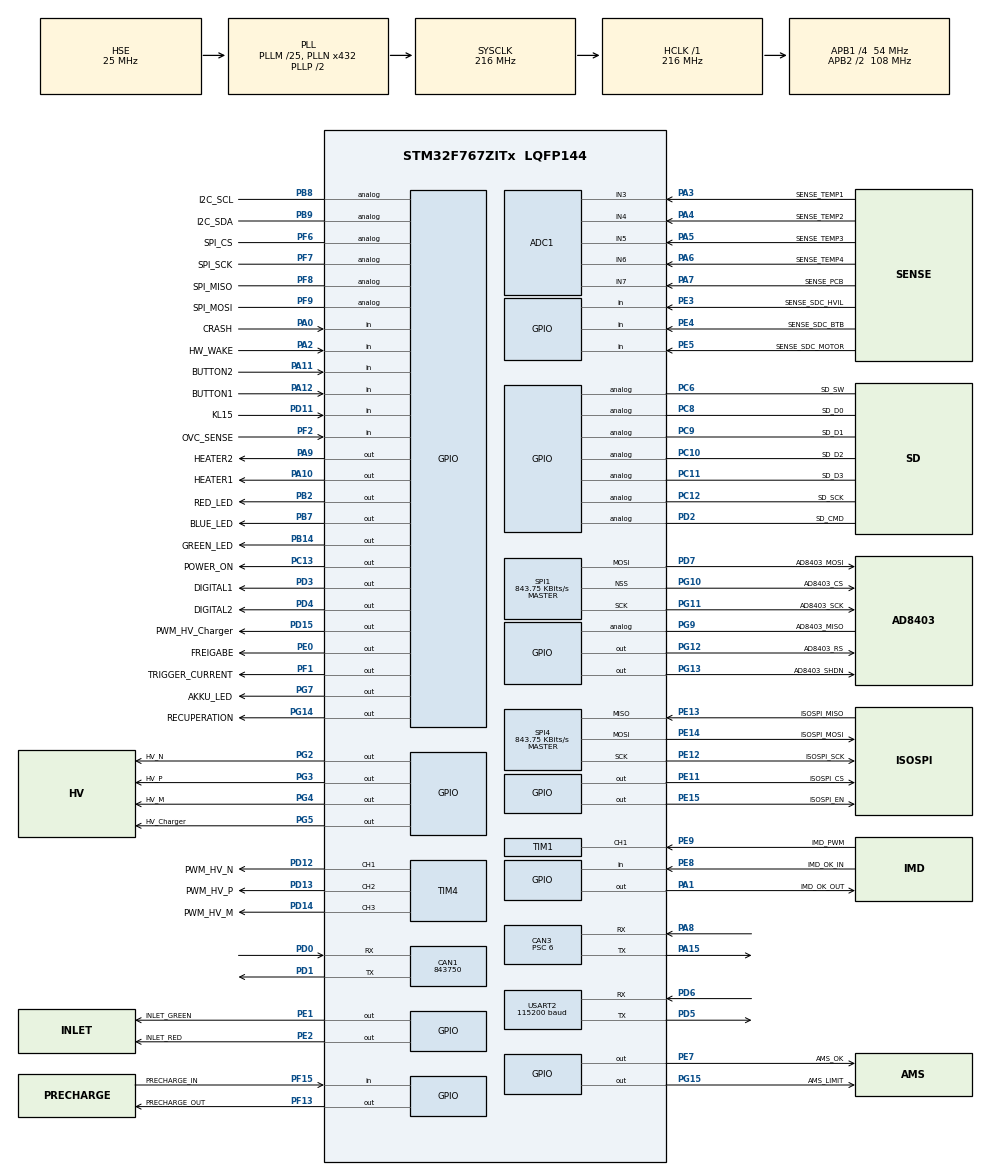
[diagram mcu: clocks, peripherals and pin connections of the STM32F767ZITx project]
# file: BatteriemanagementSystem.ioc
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ADC1.Channel-0\#ChannelRegularConversion=ADC_CHANNEL_TEMPSENSOR
ADC1.NbrOfConversion=1
ADC1.NbrOfConversionFlag=1
ADC1.Rank-0\#ChannelRegularConversion=1
ADC1.SamplingTime-0\#ChannelRegularConversion=ADC_SAMPLETIME_15CYCLES
ADC1.ScanConvMode=ADC_SCAN_DISABLE
ADC1.master=1
CAN1.BS1=CAN_BS1_2TQ
CAN1.BS2=CAN_BS2_1TQ
CAN1.CalculateBaudRate=843750
CAN1.CalculateTimeBit=1185
CAN1.CalculateTimeQuantum=296.2962962962963
CAN3.BS1=CAN_BS1_15TQ
CAN3.BS2=CAN_BS2_2TQ
CAN3.CalculateBaudRate=500000
CAN3.CalculateTimeBit=2000
CAN3.CalculateTimeQuantum=111.11111111111111
CAN3.Prescaler=6
Mcu.Family=STM32F7
Mcu.Name=STM32F767ZITx
Mcu.Package=LQFP144
NVIC.CAN3_RX0_IRQn=true\:0\:0\:false\:false\:false\:true\:true\:true
NVIC.CAN3_TX_IRQn=true\:0\:0\:false\:false\:false\:true\:true\:true
NVIC.PriorityGroup=NVIC_PRIORITYGROUP_4
NVIC.TIM1_CC_IRQn=true\:0\:0\:false\:false\:true\:true\:true\:true
PA0/WKUP.GPIO_Label=CRASH
PA0/WKUP.Signal=GPIO_Input
PA1.GPIO_Label=IMD_OK_OUT
PA1.Signal=GPIO_Output
PA10.GPIO_Label=HEATER1
PA10.Signal=GPIO_Output
PA11.GPIO_Label=BUTTON2
PA11.Signal=GPIO_Input
PA12.GPIO_Label=BUTTON1
PA12.Signal=GPIO_Input
PA13.GPIO_Label=TMS
PA13.Mode=Trace_Asynchronous_SW
PA13.Signal=SYS_JTMS-SWDIO
PA14.GPIO_Label=TCK
PA14.Mode=Trace_Asynchronous_SW
PA14.Signal=SYS_JTCK-SWCLK
PA15.Mode=CAN_Activate
PA15.Signal=CAN3_TX
PA2.GPIO_Label=HW_WAKE
PA2.Signal=GPIO_Input
PA3.GPIO_Label=SENSE_TEMP1
PA3.Signal=SharedAnalog_PA3
PA4.GPIO_Label=SENSE_TEMP2
PA4.Signal=SharedAnalog_PA4
PA5.GPIO_Label=SENSE_TEMP3
PA5.Signal=SharedAnalog_PA5
PA6.GPIO_Label=SENSE_TEMP4
PA6.Signal=SharedAnalog_PA6
PA7.GPIO_Label=SENSE_PCB
PA7.Signal=SharedAnalog_PA7
PA8.Mode=CAN_Activate
PA8.Signal=CAN3_RX
PA9.GPIO_Label=HEATER2
PA9.Signal=GPIO_Output
PB14.GPIO_Label=GREEN_LED
PB14.Signal=GPIO_Output
PB2.GPIO_Label=RED_LED
PB2.GPIO_Speed=GPIO_SPEED_FREQ_LOW
PB2.Signal=GPIO_Output
PB3.GPIO_Label=SWO
PB3.Mode=Trace_Asynchronous_SW
PB3.Signal=SYS_JTDO-SWO
PB7.GPIO_FM7=__NULL
PB7.GPIO_Label=BLUE_LED
PB7.Signal=GPIO_Output
PB8.GPIO_Label=I2C_SCL
PB8.Signal=GPIO_Analog
PB9.GPIO_Label=I2C_SDA
PB9.Signal=GPIO_Analog
PC10.GPIO_Label=SD_D2
PC10.Signal=GPIO_Analog
PC11.GPIO_Label=SD_D3
PC11.Signal=GPIO_Analog
PC12.GPIO_Label=SD_SCK
PC12.Signal=GPIO_Analog
PC13.GPIO_Label=POWER_ON
PC13.Signal=GPIO_Output
PC14/OSC32_IN.Mode=LSE-External-Oscillator
PC14/OSC32_IN.Signal=RCC_OSC32_IN
PC15/OSC32_OUT.Mode=LSE-External-Oscillator
PC15/OSC32_OUT.Signal=RCC_OSC32_OUT
PC6.GPIO_Label=SD_SW
PC6.Signal=GPIO_Analog
PC8.GPIO_Label=SD_D0
PC8.Signal=GPIO_Analog
PC9.GPIO_Label=SD_D1
PC9.Signal=GPIO_Analog
PD0.Mode=CAN_Activate
PD0.Signal=CAN1_RX
PD1.Mode=CAN_Activate
PD1.Signal=CAN1_TX
PD11.GPIO_Label=KL15
PD11.Signal=GPIO_Input
PD12.GPIO_Label=PWM_HV_N
PD12.Signal=S_TIM4_CH1
PD13.GPIO_Label=PWM_HV_P
PD13.Signal=S_TIM4_CH2
PD14.GPIO_Label=PWM_HV_M
PD14.Signal=S_TIM4_CH3
PD15.GPIO_Label=PWM_HV_Charger
PD15.Signal=GPIO_Output
PD2.GPIO_Label=SD_CMD
PD2.Signal=GPIO_Analog
PD3.GPIO_Label=DIGITAL1
PD3.Signal=GPIO_Output
PD4.GPIO_Label=DIGITAL2
PD4.Signal=GPIO_Output
PD5.Mode=Asynchronous
PD5.Signal=USART2_TX
PD6.Mode=Asynchronous
PD6.Signal=USART2_RX
PD7.GPIO_Label=AD8403_MOSI
PD7.Mode=TX_Only_Simplex_Unidirect_Master
PD7.Signal=SPI1_MOSI
PE0.GPIO_Label=FREIGABE
PE0.Signal=GPIO_Output
PE1.GPIO_Label=INLET_GREEN
PE1.Signal=GPIO_Output
PE11.GPIO_Label=ISOSPI_CS
PE11.PinState=GPIO_PIN_SET
PE11.Signal=GPIO_Output
PE12.GPIO_Label=ISOSPI_SCK
PE12.Mode=Full_Duplex_Master
PE12.Signal=SPI4_SCK
PE13.GPIO_Label=ISOSPI_MISO
PE13.Mode=Full_Duplex_Master
PE13.Signal=SPI4_MISO
PE14.GPIO_Label=ISOSPI_MOSI
PE14.Mode=Full_Duplex_Master
PE14.Signal=SPI4_MOSI
PE15.GPIO_Label=ISOSPI_EN
PE15.Signal=GPIO_Output
PE2.GPIO_Label=INLET_RED
PE2.Signal=GPIO_Output
PE3.GPIO_Label=SENSE_SDC_HVIL
PE3.Signal=GPIO_Input
PE4.GPIO_Label=SENSE_SDC_BTB
PE4.Signal=GPIO_Input
PE5.GPIO_Label=SENSE_SDC_MOTOR
PE5.Signal=GPIO_Input
PE7.GPIO_Label=AMS_OK
PE7.Signal=GPIO_Output
PE8.GPIO_Label=IMD_OK_IN
PE8.Signal=GPIO_Input
PE9.GPIO_Label=IMD_PWM
PE9.Signal=S_TIM1_CH1
PF1.GPIO_Label=TRIGGER_CURRENT
PF1.Signal=GPIO_Output
PF13.GPIO_Label=PRECHARGE_OUT
PF13.Signal=GPIO_Output
PF15.GPIO_Label=PRECHARGE_IN
PF15.Signal=GPIO_Input
PF2.GPIO_Label=OVC_SENSE
PF2.Signal=GPIO_Input
PF6.GPIO_Label=SPI_CS
PF6.Signal=GPIO_Analog
PF7.GPIO_Label=SPI_SCK
PF7.Signal=GPIO_Analog
PF8.GPIO_Label=SPI_MISO
PF8.Signal=GPIO_Analog
PF9.GPIO_Label=SPI_MOSI
PF9.Signal=GPIO_Analog
PG10.GPIO_Label=AD8403_CS
PG10.Mode=NSS_Signal_Hard_Output
PG10.Signal=SPI1_NSS
PG11.GPIO_Label=AD8403_SCK
PG11.Mode=TX_Only_Simplex_Unidirect_Master
PG11.Signal=SPI1_SCK
PG12.GPIO_Label=AD8403_RS
PG12.Signal=GPIO_Output
PG13.GPIO_Label=AD8403_SHDN
PG13.Signal=GPIO_Output
PG14.GPIO_Label=RECUPERATION
PG14.Signal=GPIO_Output
PG15.GPIO_Label=AMS_LIMIT
PG15.Signal=GPIO_Output
PG2.GPIO_Label=HV_N
PG2.Signal=GPIO_Output
PG3.GPIO_Label=HV_P
PG3.Signal=GPIO_Output
PG4.GPIO_Label=HV_M
PG4.Signal=GPIO_Output
PG5.GPIO_Label=HV_Charger
PG5.Signal=GPIO_Output
PG7.GPIO_Label=AKKU_LED
PG7.Signal=GPIO_Output
PG9.GPIO_Label=AD8403_MISO
PG9.Signal=GPIO_Analog
PH0/OSC_IN.GPIO_Label=RCC_OSC_IN
PH0/OSC_IN.Mode=HSE-External-Oscillator
PH0/OSC_IN.Signal=RCC_OSC_IN
PH1/OSC_OUT.GPIO_Label=RCC_OSC_OUT
PH1/OSC_OUT.Mode=HSE-External-Oscillator
PH1/OSC_OUT.Signal=RCC_OSC_OUT
ProjectManager.HeapSize=0x200
ProjectManager.StackSize=0x400
ProjectManager.TargetToolchain=STM32CubeIDE
RCC.48MHZClocksFreq_Value=24000000
RCC.AHBFreq_Value=216000000
RCC.APB1CLKDivider=RCC_HCLK_DIV4
RCC.APB1Freq_Value=54000000
RCC.APB1TimFreq_Value=108000000
RCC.APB2CLKDivider=RCC_HCLK_DIV2
RCC.APB2Freq_Value=108000000
RCC.APB2TimFreq_Value=216000000
RCC.CortexFreq_Value=216000000
RCC.HCLKFreq_Value=216000000
RCC.HSE_VALUE=25000000
RCC.HSI_VALUE=16000000
RCC.PLL48CLockSelection=RCC_CLK48SOURCE_PLLSAIP
RCC.PLLM=25
RCC.PLLMUL=RCC_PLL_MUL9
RCC.PLLN=432
RCC.PLLQ=8
RCC.PLLSAIP=RCC_PLLSAIP_DIV8
RCC.PLLSourceVirtual=RCC_PLLSOURCE_HSE
RCC.PRESCALERUSB=RCC_USBCLKSOURCE_PLL_DIV1_5
RCC.RCC_MCO2Source=RCC_MCO2SOURCE_HSE
RCC.RTCClockSelection=RCC_RTCCLKSOURCE_LSE
RCC.SYSCLKFreq_VALUE=216000000
RCC.SYSCLKSource=RCC_SYSCLKSOURCE_PLLCLK
RCC.SYSCLKSourceVirtual=RCC_SYSCLKSOURCE_PLLCLK
RCC.USBFreq_Value=24000000
RCC.VCOOutputFreq_Value=432000000
SH.S_TIM1_CH1.0=TIM1_CH1,PWM_Input_1
SH.S_TIM4_CH1.0=TIM4_CH1,PWM Generation1 CH1
SH.S_TIM4_CH2.0=TIM4_CH2,PWM Generation2 CH2
SH.S_TIM4_CH3.0=TIM4_CH3,PWM Generation3 CH3
SH.SharedAnalog_PA3.0=GPIO_Analog
SH.SharedAnalog_PA3.1=ADC1_IN3,IN3
SH.SharedAnalog_PA4.0=GPIO_Analog
SH.SharedAnalog_PA4.1=ADC1_IN4,IN4
SH.SharedAnalog_PA5.0=GPIO_Analog
SH.SharedAnalog_PA5.1=ADC1_IN5,IN5
SH.SharedAnalog_PA6.0=GPIO_Analog
SH.SharedAnalog_PA6.1=ADC1_IN6,IN6
SH.SharedAnalog_PA7.0=GPIO_Analog
SH.SharedAnalog_PA7.1=ADC1_IN7,IN7
SPI1.BaudRatePrescaler=SPI_BAUDRATEPRESCALER_128
SPI1.CalculateBaudRate=843.75 KBits/s
SPI1.DataSize=SPI_DATASIZE_8BIT
SPI1.Direction=SPI_DIRECTION_2LINES
SPI1.Mode=SPI_MODE_MASTER
SPI1.NSSPMode=SPI_NSS_PULSE_ENABLE
SPI1.VirtualNSS=VM_NSSHARD
SPI1.VirtualType=VM_MASTER
SPI4.BaudRatePrescaler=SPI_BAUDRATEPRESCALER_128
SPI4.CLKPhase=SPI_PHASE_2EDGE
SPI4.CLKPolarity=SPI_POLARITY_HIGH
SPI4.CRCCalculation=SPI_CRCCALCULATION_DISABLE
SPI4.CalculateBaudRate=843.75 KBits/s
SPI4.DataSize=SPI_DATASIZE_8BIT
SPI4.Direction=SPI_DIRECTION_2LINES
SPI4.FirstBit=SPI_FIRSTBIT_MSB
SPI4.Mode=SPI_MODE_MASTER
SPI4.VirtualType=VM_MASTER
TIM1.AutoReloadPreload=TIM_AUTORELOAD_PRELOAD_DISABLE
TIM1.ClockDivision=TIM_CLOCKDIVISION_DIV1
TIM1.ICPolarity_1=TIM_INPUTCHANNELPOLARITY_RISING
TIM1.Period=65535
TIM1.Prescaler=675 - 1
TIM4.Channel-PWM\ Generation1\ CH1=TIM_CHANNEL_1
TIM4.Channel-PWM\ Generation2\ CH2=TIM_CHANNEL_2
TIM4.Channel-PWM\ Generation3\ CH3=TIM_CHANNEL_3
USART2.BaudRate=115200
USART2.VirtualMode-Asynchronous=VM_ASYNC
VP_ADC1_TempSens_Input.Mode=IN-TempSens
VP_TIM1_VS_ClockSourceINT.Mode=Internal
board=NUCLEO-F767ZI

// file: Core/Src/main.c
/* USER CODE BEGIN Header */
/**
  ******************************************************************************
  * @file           : main.c
  * @brief          : Main program body
  ******************************************************************************
  * @attention
  *
  * <h2><center>&copy; Copyright (c) 2020 STMicroelectronics.
  * All rights reserved.</center></h2>
  *
  * This software component is licensed by ST under BSD 3-Clause license,
  * the "License"; You may not use this file except in compliance with the
  * License. You may obtain a copy of the License at:
  *                        opensource.org/licenses/BSD-3-Clause
  *
  ******************************************************************************
  */
/* USER CODE END Header */
#include "main.h"
#include "adc.h"
#include "can.h"
#include "spi.h"
#include "tim.h"
#include "usart.h"
#include "gpio.h"

/* USER CODE BEGIN Includes */
#include "BatteriemanagementSystem.h"
#include <math.h>
/* USER CODE END Includes */

/* USER CODE BEGIN PTD */
// TODO:
// FIXME:
// xxx: Schlechte Performance
/* USER CODE END PTD */

/* USER CODE BEGIN PV */
// ADC Array
static uint16_t ADC_VAL[8] = {0};

// Fehler Speicher CAN-Bus
uint8_t can_online = 0;

// IMD Variablen fuer Timer
static volatile uint16_t rising = 0, falling = 0;
static volatile uint8_t pwm_change = 0;
/* USER CODE END PV */

void SystemClock_Config(void);
/* USER CODE BEGIN PFP */
void checkSDC (void);
void sortCAN (void);

/* USER CODE END PFP */

int main(void)
{

  /* USER CODE BEGIN 1 */
	// BMS Statemaschine Zeitvariablen
	uint32_t timeStandby = 0, timeErrorLED = 0;
	uint32_t timeZyklus = 0, lasttimeZyklus = 0;

	// BMS Abfrage Zeitvariablen
	uint32_t timeBMSWork = 0;

	// BMS CAN-Bus Zeitvariable
	uint32_t timeBAMO = 0, timeMOTOR = 0, timeStromHV = 0;

	// Zeitvariable Precharge
	uint32_t timePrecharge = 0;

	// CAN-Bus Receive Message
	CAN_message_t RxMessage;

	// Anforderung Motorsteuergeraet Drive-Modus aktivieren
	bool ActivDrive = false;
	Statemaschine mStrg = {{Start, true, false, false, false}};

#if STROM_HV_AVAILABLE == 1
	// Stromsensor Nachrichten definieren
	stromsensor_ivtmod current, voltage1;									//voltage2, voltage3;
#endif

	// IMD Variablen fuer Berechnung
	uint32_t timer1Periode = 0, timeIMD = 0;

	// Testvariablen
	uint32_t zweisekunden = 0;

#ifdef DEBUG_DWT
	// Variablen fuer Data Watchpoint Trigger
	uint32_t DWT_count = 0, DWT_count1 = 0, DWT_count2 = 0, test = 0;
#endif
  /* USER CODE END 1 */

  /* MCU Configuration--------------------------------------------------------*/

  /* Reset of all peripherals, Initializes the Flash interface and the Systick. */
  HAL_Init();

  /* Configure the system clock */
  SystemClock_Config();

  /* USER CODE BEGIN SysInit */
	MX_USART2_UART_Init();

	// Uart initialisieren
	initBasicUart(&huart2);

#ifdef DEBUG
	app_info();
	HAL_Delay(3000);
#endif

#if MOTOR_AVAILABLE != 1
	#if TISCHAUFBAU == 1
		sdc_in.Anlassen = true;
	#endif
#endif

	uartTransmit("Start\n", 6);
  /* USER CODE END SysInit */

  /* Initialize all configured peripherals */
  MX_GPIO_Init();
  MX_CAN1_Init();
  MX_SPI4_Init();
  MX_USART2_UART_Init();
  MX_ADC1_Init();
  MX_TIM1_Init();
  MX_TIM4_Init();
  MX_SPI1_Init();
  MX_CAN3_Init();
  /* USER CODE BEGIN 2 */

	// Timer 1 fuer IMD PWM-Eingang aktivieren
	if (HAL_TIM_Base_Init(&htim1) != HAL_OK);
	if (HAL_TIM_IC_Start_IT(&htim1, TIM_CHANNEL_1) != HAL_OK);
	if (HAL_TIM_IC_Start_IT(&htim1, TIM_CHANNEL_2) != HAL_OK);
	timer1Periode = (HAL_RCC_GetPCLK2Freq() / (htim1.Init.Prescaler / 2));

	// Uart initialisieren
	initBasicUart(&huart2);

	// CAN-Bus initalisieren
	CANinit(RX_SIZE_16, TX_SIZE_16);
	CAN_config();

	// System Selbsterhaltung einschalten
	system_out.PowerOn = true;

	// BMS initialisieren
	if (bms_init() != false)
	{
		uartTransmit("BMS gestartet\n", 14);
		system_out.AmsOK = true;
		system_out.AmsLimit = true;
	}
	else
	{
		uartTransmit("BMS konnte nicht gestartet werden\n", 34);
		system_out.AmsOK = false;
		system_out.AmsLimit = false;
//		setStatus(StateError);
	}

	// IMD Fehler zuruecksetzen bei Systemstart
	system_out.ImdOK = true;

	// CAN-Nachrichten loeschen
	clearCAN();

#ifdef DEBUG
	#define MAINWHILE							"\nStarte While Schleife\n"
	uartTransmit(MAINWHILE, sizeof(MAINWHILE));
#endif

	timeZyklus = millis();

	// Nach erfolgreicher Initialisiserung aller Konfigurationen
	setState(Ready);

	ltc6811_validate_balance();
  /* USER CODE END 2 */

  /* Infinite loop */
  /* USER CODE BEGIN WHILE */
	while (1)
	{
#ifdef DEBUG_ZYKLUS
		uartTransmit("Zykluszeit:\t\t", 13);
		uartTransmitNumber(millis() - timeZyklus, 10);
		uartTransmit("\n", 1);
#endif

		lasttimeZyklus = timeZyklus;
		timeZyklus = millis();
    /* USER CODE END WHILE */

    /* USER CODE BEGIN 3 */
		// Alle Eingaenge einlesen
		readall_inputs();

		// Alle ADC einlesen
		ADC_VAL[0] = ADC_STMTemperatur();
		ADC_VAL[1] = ADC_PCBTemperatur();
		ADC_VAL[2] = ADC_KL15();
		ADC_VAL[3] = ADC_KL30_Relais();
		ADC_VAL[4] = ADC_Temp1();
		ADC_VAL[5] = ADC_Temp2();
		ADC_VAL[6] = ADC_Temp3();
		ADC_VAL[7] = ADC_Temp4();

		// Sortiere CAN-Daten auf CAN-Buffer
		sortCAN();

		// Lese IMD Status ein
		// Wenn sich der Pegel am IMD_PWM aendert
		if (pwm_change == 1)
		{
			// IMD Werte berechnen
			if (rising != 0 && falling != 0)
			{
				// Berechne DutyCycle und Frequenzy von IMD_PWM
				uint16_t imd_diff = getDifference(rising, falling);
				imd.DutyCycle = 100 - round((float)(imd_diff * 100) / (float)rising);
				imd.Frequency = timer1Periode / rising;
			}

			// Alle 5s den IMD-Status auslesen
			if (millis() > (timeIMD + 5000))
			{
				imd_status();
				timeIMD = millis();
			}

			pwm_change = 0;
		}

		// Lese CAN-Nachrichten ein
		if (CAN_available() >= 1)
		{
			CANread(&RxMessage);

			switch (RxMessage.id)
			{
#if BAMOCAR_AVAILABLE == 1
				// Bamocar ID
				case BAMOCAR_CAN_RX:
				{
					can_online |= (1 << 0);
					timeBAMO = millis();

					setStatus(StateNormal);

					break;
				}
#endif

#if MOTOR_AVAILABLE == 1
				// Motorsteuergeraet Status ID
				case MOTOR_CAN_STATUS:
				{
					can_online |= (1 << 1);
					timeMOTOR = millis();

					setStatus(StateNormal);

					mStrg.Status = RxMessage.buf[0];

					break;
				}

				// Motorsteuergeraet Digital Input ID
				case MOTOR_CAN_DIGITAL_IN:
				{
					// TODO: Zuordnung Signal Bit
					// Abfrage Anlasser, Default 1, Geschaltet 0
					if (~RxMessage.buf[2] & (1 << 7))
					{
						// Anlasser Pin von Motorsteuergeraet abspeichern
						sdc_in.Anlassen = true;
					}

					// Abrage ASR1
					if ((RxMessage.buf[5] & (1 << 0)) && ((mStrg.State & ReadyToDrive) | (mStrg.State & Drive)))
					{
						// DriveMode aktivieren
						ActivDrive = true;
					}

					break;
				}
#endif

#if STROM_HV_AVAILABLE == 1
				// Stromwert
				case STROM_HV_CAN_I:
				{
					// Speichern wenn verfuegbar, Zeit zuruecksetzen
					can_online |= (1 << 2);
					timeStromHV = millis();

					// Statemaschine setzen
					setStatus(StateNormal);

					// Stromwert uebernehmen
					current.data[0] = RxMessage.buf[0];
					current.data[1] = RxMessage.buf[1];
					current.result = (RxMessage.buf[2] << 24) | (RxMessage.buf[3] << 16) | (RxMessage.buf[4] << 8) | RxMessage.buf[5];
					break;
				}

				// Spannungswert 1
				case STROM_HV_CAN_U1:
				{
					// Spannungswerte uebernehmen
					voltage1.data[0] = RxMessage.buf[0];
					voltage1.data[1] = RxMessage.buf[1];
					voltage1.result = (RxMessage.buf[2] << 24) | (RxMessage.buf[3] << 16) | (RxMessage.buf[4] << 8) | RxMessage.buf[5];
					break;
				}

//			  // Spannungswert 2
//			  case STROM_HV_CAN_U2:
//			  {
//				  // Spannungswerte uebernehmen
//				  voltage2.data[0] = RxMessage.buf[0];
//				  voltage2.data[1] = RxMessage.buf[1];
//				  voltage2.result = (RxMessage.buf[2] << 24) | (RxMessage.buf[3] << 16) | (RxMessage.buf[4] << 8) | RxMessage.buf[5];
//				  break;
//			  }

//			  // Spannungswert 3
//			  case STROM_HV_CAN_U3:
//			  {
//				  // Spannungswerte uebernehmen
//				  voltage3.data[0] = RxMessage.buf[0];
//				  voltage3.data[1] = RxMessage.buf[1];
//				  voltage3.result = (RxMessage.buf[2] << 24) | (RxMessage.buf[3] << 16) | (RxMessage.buf[4] << 8) | RxMessage.buf[5];
//				  break;
//			  }
#endif

				default:
				{
					break;
				}
			}
		}

#if BAMOCAR_AVAILABLE == 1
		// Timeout abfrage Bamocar
		if ((Main_Statemaschine.State != Standby) && (millis() > (timeBAMO + CAN_TIMEOUT)))
		{
			// Timeout vorhanden, dann Warnung setzen
			can_online &= ~(1 << 0);
			longWarning |= (1 << 0);

			// Status setzen
			setStatus(StateWarning);
		}
#endif

#if MOTOR_AVAILABLE == 1
		// Timeout abfrage Motorsteuergeraet
		if ((Main_Statemaschine.State != Standby) && (millis() > (timeMOTOR + CAN_TIMEOUT)))
		{
			// Timeout vorhanden, dann Warnung setzen
			can_online &= ~(1 << 1);
			longWarning |= (1 << 1);

			// Status setzen
			setStatus(StateWarning);
		}
#endif

#if STROM_HV_AVAILABLE == 1
		// Timeout abfrage Stromsensor
		if ((Main_Statemaschine.State != Standby) && (millis() > (timeStromHV + CAN_TIMEOUT)))
		{
			// Timeout vorhanden, dann Warnung setzen
			can_online &= ~(1 << 2);
			longWarning |= (1 << 2);

			// Status setzen
			setStatus(StateWarning);
		}

		// Overcurrent abfragen, Software
		if (current.result > IVT_OVERCURRENT_TRESHOLD)
		{
			// Overcurrent in Software vorhanden, dann Warnung setzen
			longWarning |= (1 << 4);

			// Status setzen
			setStatus(StateWarning);
		}

		// Ueberspannung abfragen, Software
		if (voltage1.result > IVT_OVERVOLTAGE1_TRESHOLD)
		{
			// Ueberspannung in Software vorhanden, dann Warnung setzen
			longWarning |= (1 << 5);										// Warnung fuer Ueberspannung setzen
			longWarning &= ~(1 << 6);										// Warnung fuer Unterspannung zuruecksetzen

			// Status setzen
			setStatus(StateWarning);
		}
		// Unterspannung abfragen, Software
		else if (voltage1.result <= IVT_UNDERVOLTAGE1_TRESHOLD)
		{
			// Unterspannung in Software vorhanden, dann Warnung setzen
			longWarning &= ~(1 << 5);										// Warnung fuer Ueberspannung zuruecksetzen
			longWarning |= (1 << 6);										// Warnung fuer Unterspannung setzen

			// Status setzen
			setStatus(StateWarning);
		}
		// Wenn weder Unter- noch Ueberspannung vorhanden
		else
		{
			// Status setzen
			setStatus(StateNormal);
		}
#endif

		// Crash Ausgeloest
		if (system_in.Crash != 1)
		{
			// Setze BMS Error Critical und Status auf Ready
			setStatus(CriticalError);
			Main_Statemaschine.State = Ready;

			// BMS zuruecksetzen, dass kein HV mehr eingeschaltet werden kann
			system_out.Freigabe = false;
			system_out.AmsLimit = false;
			system_out.AmsOK = false;
			system_out.ImdOK = false;
			system_out.Recuperation = false;
			sdc_in.Anlassen = false;
		}

		// Wenn Statemaschine nicht im Standby ist
		if (Main_Statemaschine.State != Standby)
		{
			// Schreibe alle CAN-Nachrichten auf BUS, wenn nicht im Standby
			CANwork();

			// Shutdown-Circuit checken
			checkSDC();

			// TODO: Zellspannungen und -temperaturen in CAN-Nachrichten schreiben
			// TODO: Timeout fuer LTC6811
			// BMS-Work Funktion nur alle 100ms aufrufen
			if (millis() > (timeBMSWork + BMS_WORK_TIME))
			{
				bms_work();
				timeBMSWork = millis();
			}

			// 2s Task
			if (millis() > (zweisekunden + 2000))
			{

				zweisekunden = millis();
			}
		}

		// Statemaschine keine Fehler
		if (Main_Statemaschine.Normal)
		{
			leuchten_out.RedLed = false;
			leuchten_out.GreenLed = true;

			system_out.AmsLimit = true;
		}

		// Statemaschine hat Warnungen
		if (Main_Statemaschine.Warning)
		{
			if (millis() > (timeErrorLED + 1000))
			{
				leuchten_out.RedLed = !leuchten_out.RedLed;
				timeErrorLED = millis();
			}

			leuchten_out.GreenLed = true;
			system_out.AmsLimit = true;
		}

		// Statemaschine hat Error
		if (Main_Statemaschine.Error)
		{
			if (millis() > (timeErrorLED + 1000))
			{
				leuchten_out.RedLed = !leuchten_out.RedLed;
				timeErrorLED = millis();
			}

			leuchten_out.GreenLed = false;
			system_out.AmsLimit = false;
		}

		// Statemaschine hat Kritische Fehler
		if (Main_Statemaschine.CriticalError)
		{
			leuchten_out.RedLed = true;
			leuchten_out.GreenLed = false;

			system_out.AmsLimit = false;
		}

		// Statemaschine vom Batteriemanagement-System
		switch (Main_Statemaschine.State)
		{
			// State Ready, Vorbereiten des Batteriemanagement
			case Ready:
			{
				// Solange kein kritischer Fehler auftritt
				if (!(Main_Statemaschine.CriticalError))
				{
					komfort_out.IsoSPI_EN = true;
					ISOSPI_ENABLE();										// Enable IsoSPI nach Standby
					setState(KL15);
				}

				// Zeitvariablen zuruecksetzen
				timeMOTOR = millis();
				timeBAMO = millis();
				timeStromHV = millis();

				break;
			}

			// State KL15, wenn Schluessel auf Position 2, KL15 eingeschaltet
			case KL15:
			{
				// Wenn Anlassen aktiviert wird
				if (sdc_in.Anlassen == true)
				{
					// Solange kein kritischer Fehler auftritt
					if (!(Main_Statemaschine.CriticalError))
					{
						system_out.AmsOK = true;

						setState(Anlassen);
					}
				}

				// Falls KL15 abfaellt und der Schluessel abgezogen wird
				if (system_in.KL15 == 1)
				{
					setState(Standby);
					timeStandby = millis();
				}

				break;
			}

			// State Anlassen, wenn Schluessel auf Position 3 und keine kritischen Fehler, Anlasser einschalten
			case Anlassen:
			{
				// Wenn Anlassen aktiviert wird
				if (mStrg.State == Precharge)
				{
					// Solange kein kritischer Fehler auftritt
					if (!(Main_Statemaschine.CriticalError))
					{
						// Precharge Relais aktivieren
						highcurrent_out.PrechargeOut = true;

						setState(Precharge);
						timePrecharge = millis();
					}
				}

				// Falls KL15 abfaellt und der Schluessel abgezogen wird
				if (system_in.KL15 == 1)
				{
					setState(Standby);
					timeStandby = millis();
				}

				break;
			}

			// State Precharge, lade HV-Kreis und warte bis aufgeladen ist
			case Precharge:
			{
				// Wenn Precharge nach 10s nicht Abgeschlossen werden konnte
				if (millis() > (timePrecharge + 10000))
				{
					// Precharge Relais abschalten und kritischer Fehler
					highcurrent_out.PrechargeOut = false;
					setStatus(CriticalError);
				}

				// Wenn Precharge angeschlossen ist
				if ((sdc_in.PrechargeIn == 0) && (millis() > (timePrecharge + 5000)))
				{
					// HV+ Relais activieren
//					system_out.HV_P = true;
					HAL_GPIO_WritePin(PWM_HV_Charger_GPIO_Port, PWM_HV_Charger_Pin, GPIO_PIN_SET);

					setState(ReadyToDrive);
				}

				// Falls KL15 abfaellt und der Schluessel abgezogen wird
				if (system_in.KL15 == 1)
				{
					if (sdc_in.PrechargeIn == 1)
					{
						// Precharge wieder abschalten
						highcurrent_out.PrechargeOut = false;
					}

					setState(Standby);
					timeStandby = millis();
				}

				break;
			}

			// State ReadyToDrive, wenn SDC OK ist
			case ReadyToDrive:
			{
				// Nach 10s nach dem Precharge gestartet wurde, wird das Precharge Relais wieder abgeschaltet
				if ((highcurrent_out.PrechargeOut == true) && (millis() > (timePrecharge + 10000)))
				{
					highcurrent_out.PrechargeOut = false;
				}

				// Sobald ActivDrive aktiviert ist in den Drive Modus gehen und Freigabe an Bamocar senden
				if (ActivDrive && (highcurrent_out.PrechargeOut == false))
				{
					// Freigabe fuer Bamocar aktivieren
					system_out.Freigabe = true;

					setState(Drive);
				}

				// Falls KL15 abfaellt und der Schluessel abgezogen wird
				if (system_in.KL15 == 1)
				{
					system_out.Freigabe = false;
					ActivDrive = false;

					setState(Standby);
					timeStandby = millis();
				}

				break;
			}

			// State Drive, wenn Fahrmodus manuell aktiviert wird
			case Drive:
			{
				// Falls KL15 abfaellt und der Schluessel abgezogen wird
				if (system_in.KL15 == 1)
				{
					system_out.Freigabe = false;
					ActivDrive = false;

					setState(Standby);
					timeStandby = millis();
				}

				if (mStrg.State == KL15)
				{
					ActivDrive = false;
					setState(ReadyToDrive);
				}

				break;
			}

			// State Standby, wenn Schluessel gezogen wird, KL15 ausgeschaltet
			case Standby:
			{
				// Fuer 5min warten und BMS weiterhin aktiv halten
				if (millis() > (timeStandby + STANDBYTIME))
				{
					setState(Ausschalten);
				}
				// Falls innerhalb der 5min die KL15 wieder aktiviert wird
				else if (system_in.KL15 != 1)
				{
					setState(Ready);
				}

				// Fuer 5s warten bis BMS HV-Relais abschaltet, Anlassen zuruecksetzen
				if (millis() > (timeStandby + HVRELAISTIME))
				{
					sdc_in.Anlassen = false;
					komfort_out.IsoSPI_EN = false;
					ISOSPI_DISABLE();										// Disable IsoSPI nach 5s im Standby

					HAL_GPIO_WritePin(PWM_HV_Charger_GPIO_Port, PWM_HV_Charger_Pin, GPIO_PIN_RESET);
				}

				break;
			}

			// State Ausschalten, wenn Standby State laenger als 5min dauert
			case Ausschalten:
			{
				// Alle Ausgaenge auf Null setzen
				system_out.systemoutput = 0;
				highcurrent_out.high_out = 0;
				leuchten_out.ledoutput = 0;
				sdc_in.sdcinput = 0;

				break;
			}

			// Falls kein State zutrifft, dann kritischer Fehler
			default:
			{
				uartTransmit("BMS Kritischer Fehler While\n!", 30);
				setStatus(CriticalError);

				break;
			}
		}

		// Alle Ausgaenge schreiben
		writeall_outputs();
	}
  /* USER CODE END 3 */
}

void SystemClock_Config(void)
{
  RCC_OscInitTypeDef RCC_OscInitStruct = {0};
  RCC_ClkInitTypeDef RCC_ClkInitStruct = {0};

  /** Configure LSE Drive Capability
  */
  HAL_PWR_EnableBkUpAccess();

  /** Configure the main internal regulator output voltage
  */
  __HAL_RCC_PWR_CLK_ENABLE();
  __HAL_PWR_VOLTAGESCALING_CONFIG(PWR_REGULATOR_VOLTAGE_SCALE1);

  /** Initializes the RCC Oscillators according to the specified parameters
  * in the RCC_OscInitTypeDef structure.
  */
  RCC_OscInitStruct.OscillatorType = RCC_OSCILLATORTYPE_HSE;
  RCC_OscInitStruct.HSEState = RCC_HSE_ON;
  RCC_OscInitStruct.PLL.PLLState = RCC_PLL_ON;
  RCC_OscInitStruct.PLL.PLLSource = RCC_PLLSOURCE_HSE;
  RCC_OscInitStruct.PLL.PLLM = 25;
  RCC_OscInitStruct.PLL.PLLN = 432;
  RCC_OscInitStruct.PLL.PLLP = RCC_PLLP_DIV2;
  RCC_OscInitStruct.PLL.PLLQ = 8;
  RCC_OscInitStruct.PLL.PLLR = 2;
  if (HAL_RCC_OscConfig(&RCC_OscInitStruct) != HAL_OK)
  {
    Error_Handler();
  }

  /** Activate the Over-Drive mode
  */
  if (HAL_PWREx_EnableOverDrive() != HAL_OK)
  {
    Error_Handler();
  }

  /** Initializes the CPU, AHB and APB buses clocks
  */
  RCC_ClkInitStruct.ClockType = RCC_CLOCKTYPE_HCLK|RCC_CLOCKTYPE_SYSCLK
                              |RCC_CLOCKTYPE_PCLK1|RCC_CLOCKTYPE_PCLK2;
  RCC_ClkInitStruct.SYSCLKSource = RCC_SYSCLKSOURCE_PLLCLK;
  RCC_ClkInitStruct.AHBCLKDivider = RCC_SYSCLK_DIV1;
  RCC_ClkInitStruct.APB1CLKDivider = RCC_HCLK_DIV4;
  RCC_ClkInitStruct.APB2CLKDivider = RCC_HCLK_DIV2;

  if (HAL_RCC_ClockConfig(&RCC_ClkInitStruct, FLASH_LATENCY_7) != HAL_OK)
  {
    Error_Handler();
  }
}

/* USER CODE BEGIN 4 */
// Check Shutdown-Circuit, wenn nicht OK, dann Fehler setzen
void checkSDC (void)
//----------------------------------------------------------------------
{
	sdc_in.SDC_OK = true;

#if IMD_AVAILABLE == 1
	// IMD abfragen, wenn angeschlossen und OK, Pin am uC ist 0, Wenn nicht Pin am uC ist 1
	if (sdc_in.IMD_OK_IN == 1)
	{
		setStatus(StateError);
		sdc_in.SDC_OK = false;
	}
#endif

#if BAMOCAR_AVAILABLE == 1
	// HV-Stecker abfragen
	if (sdc_in.HVIL == 1)
	{
		setStatus(StateError);
		sdc_in.SDC_OK = false;
	}

	// BTB-Eingang abfragen
	if (sdc_in.BTB_SDC == 1)
	{
		setStatus(StateError);
		sdc_in.SDC_OK = false;
	}
#endif

#if MOTOR_AVAILABLE == 1
	// Motor-Eingang abfragen
	if (sdc_in.MotorSDC == 1)
	{
		setStatus(StateWarning);
		sdc_in.SDC_OK = false;
	}
#endif

	if (sdc_in.SDC_OK == 1)
	{
		setStatus(StateNormal);
	}
}
//----------------------------------------------------------------------

// Sortiere CAN Daten
//----------------------------------------------------------------------
void sortCAN (void)
{
	// Digital-Ausgaenge
	CAN_Output_PaketListe[1].msg.buf[0] = system_out.systemoutput;
	CAN_Output_PaketListe[1].msg.buf[1] = highcurrent_out.high_out;
	CAN_Output_PaketListe[1].msg.buf[2] = leuchten_out.ledoutput;
	CAN_Output_PaketListe[1].msg.buf[3] = komfort_out.komfortoutput;
	CAN_Output_PaketListe[1].msg.buf[4] = 0;

	// Digital-Eingaenge
	CAN_Output_PaketListe[2].msg.buf[0] = 0;
	CAN_Output_PaketListe[2].msg.buf[1] = system_in.systeminput;
	CAN_Output_PaketListe[2].msg.buf[2] = sdc_in.sdcinput;
	CAN_Output_PaketListe[2].msg.buf[3] = komfort_in.komfortinput;

	// Analogeingaenge
	CAN_Output_PaketListe[3].msg.buf[0] = ADC_VAL[0];
	CAN_Output_PaketListe[3].msg.buf[1] = (ADC_VAL[0] >> 8) | (ADC_VAL[1] << 4);
	CAN_Output_PaketListe[3].msg.buf[2] = (ADC_VAL[1] >> 4);
	CAN_Output_PaketListe[3].msg.buf[3] = ADC_VAL[2];
	CAN_Output_PaketListe[3].msg.buf[4] = (ADC_VAL[2] >> 8) | (ADC_VAL[3] << 4);
	CAN_Output_PaketListe[3].msg.buf[5] = (ADC_VAL[3] >> 4);
	CAN_Output_PaketListe[3].msg.buf[6] = 0;
	CAN_Output_PaketListe[3].msg.buf[7] = 0;

	// Temperatureingaenge
	CAN_Output_PaketListe[4].msg.buf[0] = ADC_VAL[4];
	CAN_Output_PaketListe[4].msg.buf[1] = (ADC_VAL[4] >> 8) | (ADC_VAL[7] << 4);
	CAN_Output_PaketListe[4].msg.buf[2] = (ADC_VAL[5] >> 4);
	CAN_Output_PaketListe[4].msg.buf[3] = ADC_VAL[6];
	CAN_Output_PaketListe[4].msg.buf[4] = (ADC_VAL[6] >> 8) | (ADC_VAL[7] << 4);
	CAN_Output_PaketListe[4].msg.buf[5] = (ADC_VAL[7] >> 4);
	CAN_Output_PaketListe[4].msg.buf[6] = 0;
	CAN_Output_PaketListe[4].msg.buf[7] = 0;

	// Batteriemanagement Status
	CAN_Output_PaketListe[5].msg.buf[0] = Main_Statemaschine.Status;
	CAN_Output_PaketListe[5].msg.buf[1] = longWarning;
	CAN_Output_PaketListe[5].msg.buf[2] = longError;
	CAN_Output_PaketListe[5].msg.buf[3] = can_online;

	// IMD Status
	CAN_Output_PaketListe[6].msg.buf[0] = imd.status[0];
	CAN_Output_PaketListe[6].msg.buf[1] = imd.status[1];
	CAN_Output_PaketListe[6].msg.buf[2] = imd.status[2];
	CAN_Output_PaketListe[6].msg.buf[3] = imd.status[3];
	CAN_Output_PaketListe[6].msg.buf[4] = imd.status[4];
}
//----------------------------------------------------------------------

// Timer Interrupt
//----------------------------------------------------------------------
void HAL_TIM_IC_CaptureCallback (TIM_HandleTypeDef *htim)
{
	// Timer 1 fuer IMD PWM-Auswertung
	if (htim == &htim1)
	{
		pwm_change = 1;
		if (htim->Channel == HAL_TIM_ACTIVE_CHANNEL_1)
		{
			rising = calculateMovingAverage(rising, HAL_TIM_ReadCapturedValue(&htim1, TIM_CHANNEL_1), 10);
		}
		else if (htim->Channel == HAL_TIM_ACTIVE_CHANNEL_2)
		{
			falling = calculateMovingAverage(falling, HAL_TIM_ReadCapturedValue(&htim1, TIM_CHANNEL_2), 10);
		}
	}
}
//----------------------------------------------------------------------
/* USER CODE END 4 */

void Error_Handler(void)
{
  /* USER CODE BEGIN Error_Handler_Debug */
	// User can add his own implementation to report the HAL error return state
	__disable_irq();														// Interrupts deaktivieren

	// Schalte Fehler LED ein
	leuchten_out.RedLed = 1;												// Setze Variable
	HAL_GPIO_WritePin(RED_LED_GPIO_Port, RED_LED_Pin, leuchten_out.RedLed);	// Fehler LED einschalten

	// Schalte Ok LED aus
	leuchten_out.GreenLed = 0;												// Zuruechsetzen Variable
	HAL_GPIO_WritePin(GREEN_LED_GPIO_Port, GREEN_LED_Pin, leuchten_out.GreenLed);	// Fehler LED ausschalten

	// Sende Nachricht auf Uart-Interface
#ifdef DEBUG
#define STRING_ERROR_HANDLER					"Error Handler wird ausgefuehrt!!!"
	uartTransmit(STRING_ERROR_HANDLER, sizeof(STRING_ERROR_HANDLER));
#endif
	// Beginne Endlosschleife nachdem Fehler aufgetreten ist
	while (1)
	{

	}
  /* USER CODE END Error_Handler_Debug */
}
#ifdef USE_FULL_ASSERT
/**
  * @brief  Reports the name of the source file and the source line number
  *         where the assert_param error has occurred.
  * @param  file: pointer to the source file name
  * @param  line: assert_param error line source number
  * @retval None
  */
void assert_failed(uint8_t *file, uint32_t line)
{
  /* USER CODE BEGIN 6 */
	// User can add his own implementation to report the file name and line number,
	// tex: printf("Wrong parameters value: file %s on line %d\r\n", file, line) */
  /* USER CODE END 6 */
}
#endif /* USE_FULL_ASSERT */
